# PIC32CX1025MTSH128S1 register map
Vendor: Microchip Technology; Series: PIC32CXMTSH; File version: 0
CPU: CM4 r0p1, selectable endian, MPU, FPU, 4 interrupt priority bits, 96 interrupts
Registers are 32-bit, read-write, reset 0x0 unless marked. A register's access mark holds for its fields unless they carry their own. Offsets are from the block's base; [hi:lo] are bit positions; lines under a group give offsets from that group; {n}, {i} and the like mark numbered series; 'fields as' and 'values as' point back to an identical list; <NAME> marks a mode.

## PIO0 — Parallel Input/Output Controller
Base 0x40048000; register names take the prefix PIO_
Same registers: PIO1 0x4800C000
{0x0+0x40*i} PIO_GROUP[{i}] (i=0..2) group
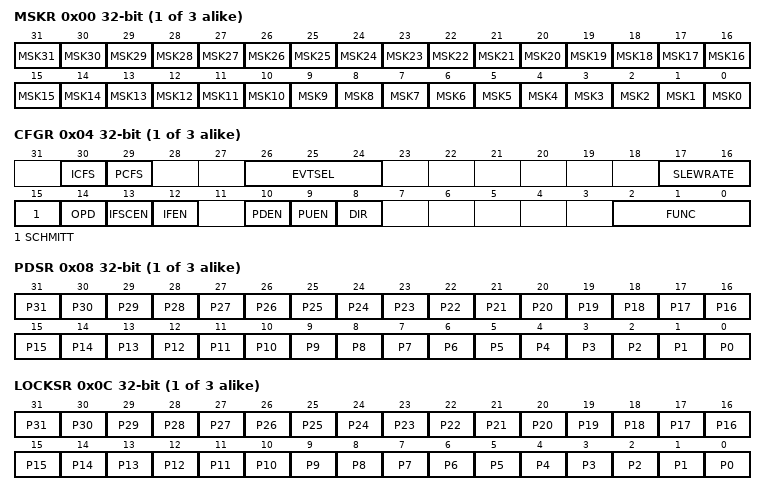
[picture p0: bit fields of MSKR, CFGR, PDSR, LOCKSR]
  0x00 MSKR — PIO Mask Register
    [all] fields
      0=DISABLED (Writing the PIO_CFGRx, PIO_ODSRx or PIO_IOFRx does not affect the corresponding I/O line configuration.); 1=ENABLED (Writing the PIO_CFGRx, PIO_ODSRx or PIO_IOFRx updates the corresponding I/O line configuration.)
    [n] MSK{n} (n=0..31) — PIO Line {n} Mask
  0x04 CFGR — PIO Configuration Register
    [30] ICFS — Interrupt Configuration Freeze Status (read-only)
      0=NOT_FROZEN (The fields are not frozen and can be written for this I/O line.); 1=FROZEN (The fields are frozen and cannot be written for this I/O line. Only a hardware reset can release these fields.)
    [29] PCFS — Physical Configuration Freeze Status (read-only)
      values as ICFS
    [26:24] EVTSEL — Event Selection
      0=FALLING (Event detection on input falling edge); 1=RISING (Event detection on input rising edge); 2=BOTH (Event detection on input both edge); 3=LOW (Event detection on low level input); 4=HIGH (Event detection on high level input)
    [17:16] SLEWRATE
      0=FAST (Fast slew rate); 1=MEDIUMFAST (Medium-fast slew rate); 2=MEDIUM (Medium slew rate); 3=SLOW (Slow slew rate)
    [15] SCHMITT — Schmitt Trigger
      0=ENABLED (Schmitt trigger is enabled for the selected I/O lines.); 1=DISABLED (Schmitt trigger is disabled for the selected I/O lines.)
    [14] OPD — Open-Drain
      0=DISABLED (The open-drain is disabled for the selected I/O lines. I/O lines are driven at high- and low-level.); 1=ENABLED (The open-drain is enabled for the selected I/O lines. I/O lines are driven at low-level only.)
    [13] IFSCEN — Input Filter Slow Clock Enable
      0=DISABLED (The glitch filter is able to filter glitches with a duration < tmck/2 for the selected I/O lines.); 1=ENABLED (The debouncing filter is able to filter pulses with a duration < tdiv_slck/2 for the selected I/O lines.)
    [12] IFEN — Input Filter Enable
      0=DISABLED (The input filter is disabled for the selected I/O lines.); 1=ENABLED (The input filter is enabled for the selected I/O lines.)
    [10] PDEN — Pull-Down Enable
      0=DISABLED (Pull-Down is disabled for the selected I/O lines.); 1=ENABLED (Pull-Down is enabled for the selected I/O lines only if PUEN is 0.)
    [9] PUEN — Pull-Up Enable
      0=DISABLED (Pull-Up is disabled for the selected I/O lines.); 1=ENABLED (Pull-Up is enabled for the selected I/O lines.)
    [8] DIR — Direction
      0=INPUT (The selected I/O lines are pure inputs.); 1=OUTPUT (The selected I/O lines are enabled in output.)
    [2:0] FUNC — I/O Line Function
      0=GPIO (Select the PIO mode for the selected I/O lines.); 1=PERIPH_A (Select the peripheral A for the selected I/O lines.); 2=PERIPH_B (Select the peripheral B for the selected I/O lines.); 3=PERIPH_C (Select the peripheral C for the selected I/O lines.); 4=PERIPH_D (Select the peripheral D for the selected I/O lines.)
  0x08 PDSR ro — PIO Pin Data Status Register
    [n] P{n} (n=0..31) — Input Data Status
  0x0C LOCKSR ro — PIO Lock Status Register
    [n] P{n} (n=0..31) — Lock Status
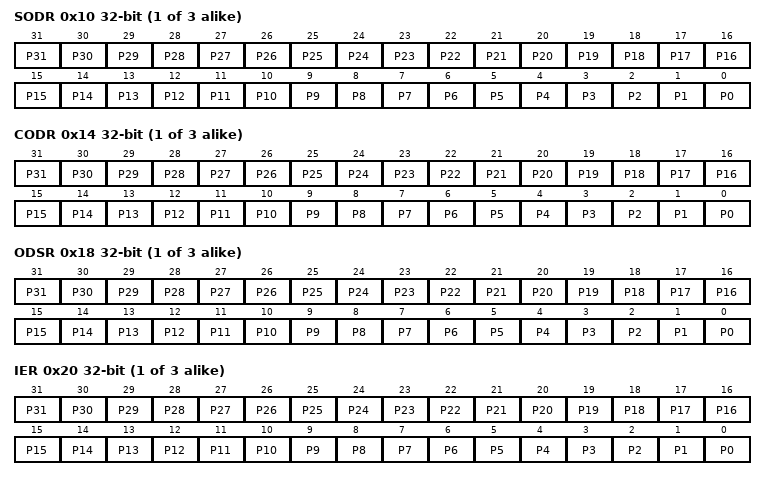
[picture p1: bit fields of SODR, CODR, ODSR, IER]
  0x10 SODR wo — PIO Set Output Data Register
    [n] P{n} (n=0..31) — Set Output Data
  0x14 CODR wo — PIO Clear Output Data Register
    [n] P{n} (n=0..31) — Clear Output Data
  0x18 ODSR — PIO Output Data Status Register
    [n] P{n} (n=0..31) — Output Data Status
  0x20 IER wo — PIO Interrupt Enable Register
    [n] P{n} (n=0..31) — Input Change Interrupt Enable
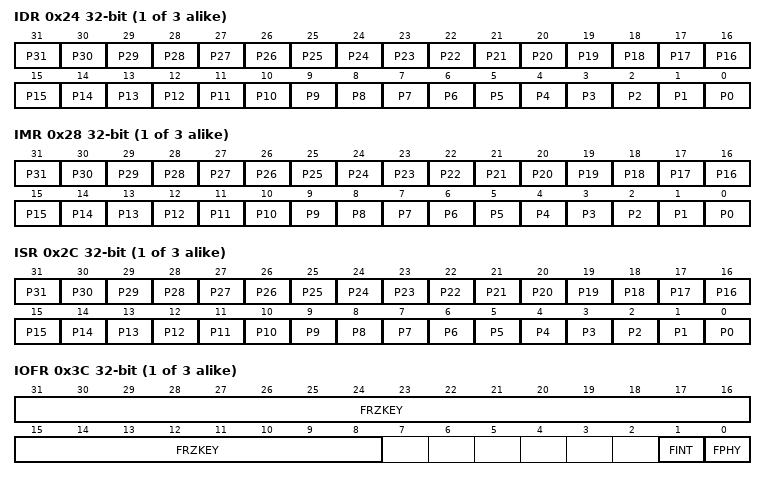
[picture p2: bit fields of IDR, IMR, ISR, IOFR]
  0x24 IDR wo — PIO Interrupt Disable Register
    [n] P{n} (n=0..31) — Input Change Interrupt Disable
  0x28 IMR ro — PIO Interrupt Mask Register
    [n] P{n} (n=0..31) — Input Change Interrupt Mask
  0x2C ISR ro — PIO Interrupt Status Register
    [n] P{n} (n=0..31) — Input Change Interrupt Status
  0x3C IOFR wo — PIO I/O Freeze Configuration Register
    [31:8] FRZKEY — Freeze Key
      0x494F46=PASSWD (Writing any other value in this field aborts the write operation of the WPEN bit.)
    [1] FINT — Freeze Interrupt Configuration
    [0] FPHY — Freeze Physical Configuration
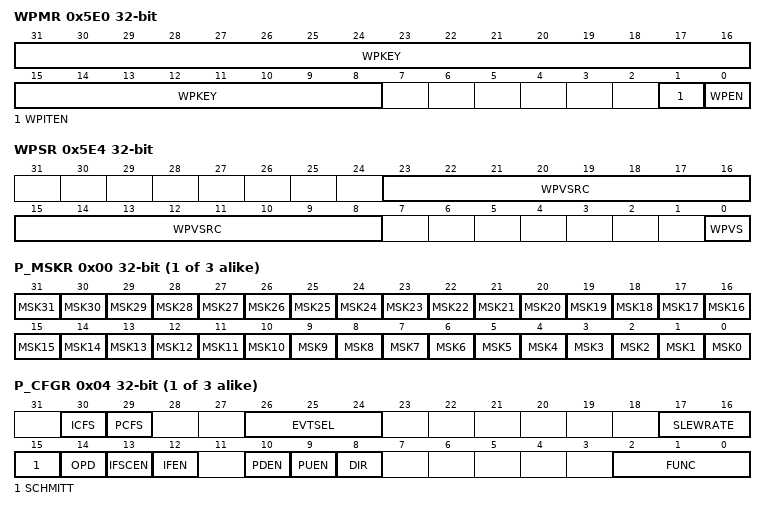
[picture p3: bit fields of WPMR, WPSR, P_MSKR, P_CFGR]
0x5E0 WPMR — PIO Write Protection Mode Register
  [31:8] WPKEY — Write Protection Key
    0x50494F=PASSWD (Writing any other value in this field aborts the write operation of the WPEN bit. Always reads as 0.)
  [1] WPITEN — Write Protection Interrupt Enable
  [0] WPEN — Write Protection Enable
0x5E4 WPSR ro — PIO Write Protection Status Register
  [23:8] WPVSRC — Write Protection Violation Source
  [0] WPVS — Write Protection Violation Status
{0x1000+0x40*i} PIO_P[{i}] (i=0..2) group
  0x00 P_MSKR — PIO Privilege Mask Register (p_iogroup = 0)
    [all] fields
      0=DISABLED (Writing the PIO_P_CFGRx, PIO_P_ODSRx or PIO_P_IOFRx does not affect the corresponding I/O line configuration.); 1=ENABLED (Writing the PIO_P_CFGRx, PIO_P_ODSRx or PIO_P_IOFRX updates the corresponding I/O line configuration.)
    [n] MSK{n} (n=0..31) — PIO Line {n} Mask
  0x04 P_CFGR — PIO Privilege Configuration Register (p_iogroup = 0)
    [30] ICFS — Interrupt Configuration Freeze Status (read-only)
      values as PIO_GROUP[0].CFGR.ICFS
    [29] PCFS — Physical Configuration Freeze Status (read-only)
      values as PIO_GROUP[0].CFGR.ICFS
    [26:24] EVTSEL — Event Selection
      values as PIO_GROUP[0].CFGR.EVTSEL
    [17:16] SLEWRATE
      0=FAST (Slow slew rate); 1=MEDIUMFAST (Medium-fast slew rate); 2=MEDIUM (Medium slew rate); 3=SLOW (Slow slew rate)
    [15] SCHMITT — Schmitt Trigger
      values as PIO_GROUP[0].CFGR.SCHMITT
    [14] OPD — Open-Drain
      values as PIO_GROUP[0].CFGR.OPD
    [13] IFSCEN — Input Filter Slow Clock Enable
    [12] IFEN — Input Filter Enable
      values as PIO_GROUP[0].CFGR.IFEN
    [10] PDEN — Pull-Down Enable
      values as PIO_GROUP[0].CFGR.PDEN
    [9] PUEN — Pull-Up Enable
      values as PIO_GROUP[0].CFGR.PUEN
    [8] DIR — Direction
      values as PIO_GROUP[0].CFGR.DIR
    [2:0] FUNC — I/O Line Function
      values as PIO_GROUP[0].CFGR.FUNC
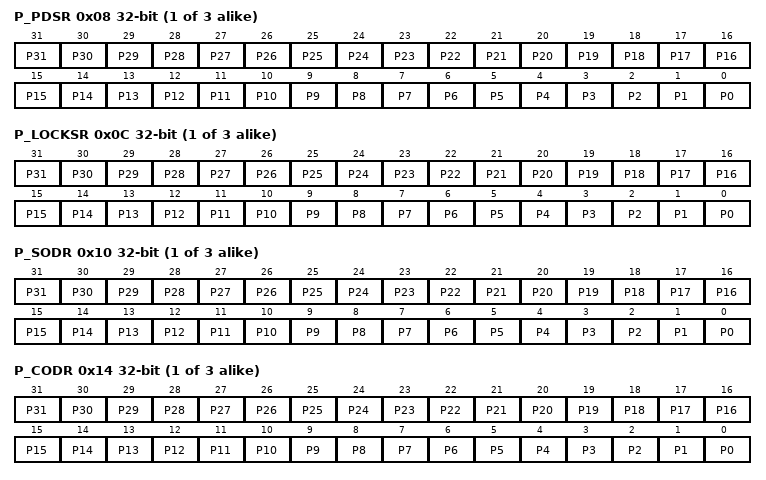
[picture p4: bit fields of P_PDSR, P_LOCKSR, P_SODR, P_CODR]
  0x08 P_PDSR ro — PIO Privilege Pin Data Status Register (p_iogroup = 0)
    [n] P{n} (n=0..31) — Input Data Status
  0x0C P_LOCKSR ro — PIO Privilege Lock Status Register (p_iogroup = 0)
    [n] P{n} (n=0..31) — Lock Status
  0x10 P_SODR wo — PIO Privilege Set Output Data Register (p_iogroup = 0)
    [n] P{n} (n=0..31) — Set Output Data
  0x14 P_CODR wo — PIO Privilege Clear Output Data Register (p_iogroup = 0)
    [n] P{n} (n=0..31) — Clear Output Data
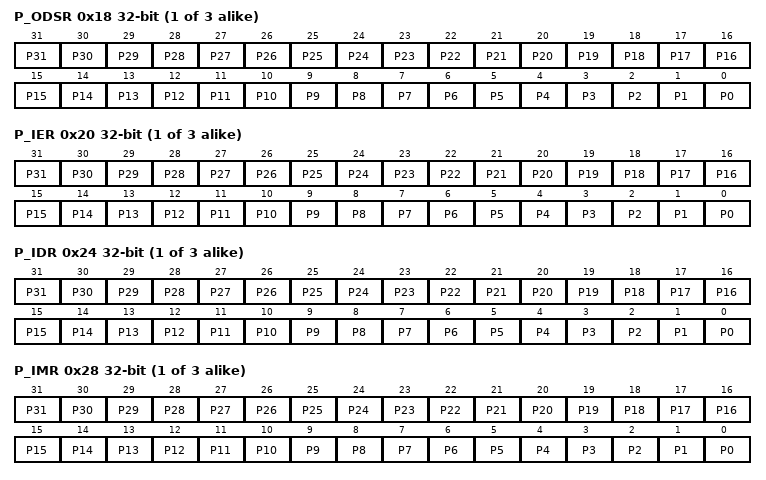
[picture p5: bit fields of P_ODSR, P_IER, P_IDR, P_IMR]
  0x18 P_ODSR — PIO Privilege Output Data Status Register (p_iogroup = 0)
    [n] P{n} (n=0..31) — Output Data Status
  0x20 P_IER wo — PIO Privilege Interrupt Enable Register (p_iogroup = 0)
    [n] P{n} (n=0..31) — Input Change Interrupt Enable
  0x24 P_IDR wo — PIO Privilege Interrupt Disable Register (p_iogroup = 0)
    [n] P{n} (n=0..31) — Input Change Interrupt Disable
  0x28 P_IMR ro — PIO Privilege Interrupt Mask Register (p_iogroup = 0)
    [n] P{n} (n=0..31) — Input Change Interrupt Mask
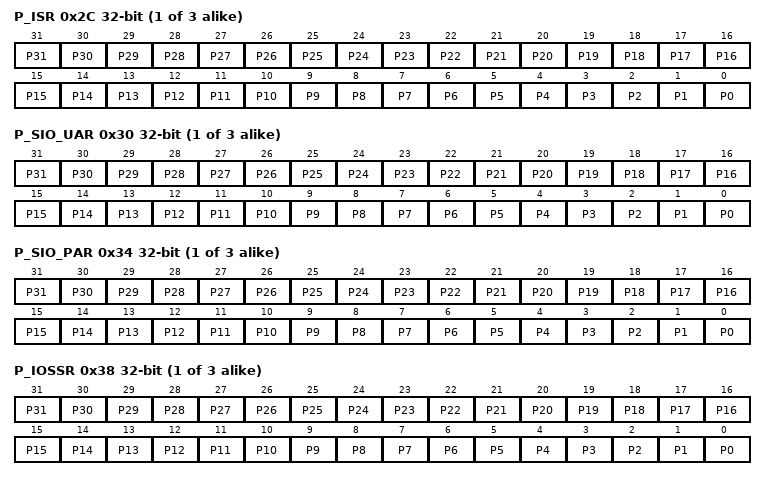
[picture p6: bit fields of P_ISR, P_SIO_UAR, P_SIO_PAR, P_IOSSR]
  0x2C P_ISR ro — PIO Privilege Interrupt Status Register (p_iogroup = 0)
    [n] P{n} (n=0..31) — Input Change Interrupt Status
  0x30 P_SIO_UAR wo — PIO Privilege Set I/O User Register (p_iogroup = 0)
    [n] P{n} (n=0..31) — Set I/O in User-Access mode
  0x34 P_SIO_PAR wo — PIO Privilege Set I/O Privilege Register (p_iogroup = 0)
    [n] P{n} (n=0..31) — Set I/O in Privileged-Access mode
  0x38 P_IOSSR ro — PIO Privilege I/O Security Status Register (p_iogroup = 0)
    [all] fields
      0=PRIVILEGED_ACCESS (The I/O line of the I/O group 0 is in Privileged-Access mode.); 1=USER_ACCESS (The I/O line of the I/O group 0 is in User-Access mode.)
    [n] P{n} (n=0..31) — I/O Security Status
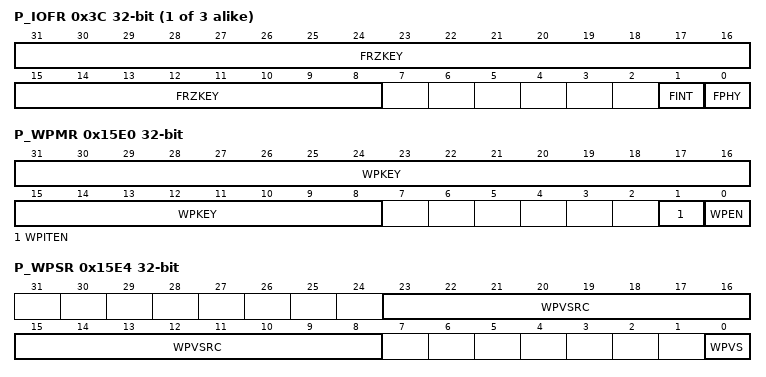
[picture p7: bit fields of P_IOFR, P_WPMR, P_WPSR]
  0x3C P_IOFR wo — PIO Privilege I/O Freeze Configuration Register (p_iogroup = 0)
    fields as PIO_GROUP[0].IOFR
0x1500 P_SCDR — PIO Privilege Slow Clock Divider Debouncing Register
  [13:0] DIV — Slow Clock Divider Selection for Debouncing
0x15E0 P_WPMR — PIO Privilege Write Protection Mode Register
  [31:8] WPKEY — Write Protection Key
    0x50494F=PASSWD (Writing any other value in this field aborts the write operation of WPEN. Always reads as 0.)
  [1] WPITEN — Write Protection Interrupt Enable
  [0] WPEN — Write Protection Enable
0x15E4 P_WPSR ro — PIO Privilege Write Protection Status Register
  fields as WPSR

## Notices in the file
Copyright (c) 2023 Microchip Technology Inc.
SPDX-License-Identifier: Apache-2.0
Licensed under the Apache License, Version 2.0 (the "License");
you may not use this file except in compliance with the License.
You may obtain a copy of the License at
http://www.apache.org/licenses/LICENSE-2.0
Unless required by applicable law or agreed to in writing, software
distributed under the License is distributed on an "AS IS" BASIS,
WITHOUT WARRANTIES OR CONDITIONS OF ANY KIND, either express or implied.
See the License for the specific language governing permissions and
limitations under the License.
